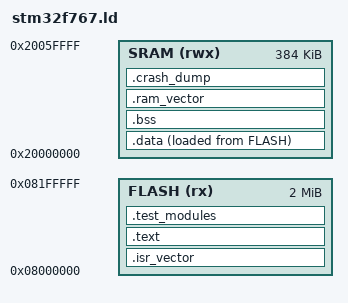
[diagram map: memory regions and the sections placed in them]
/**
 * @file stm32f767.ld
 * @brief STM32F767ZIT6 链接脚本
 */

/*============================================================================
 * 内存布局
 *============================================================================*/

MEMORY
{
    /* Flash: 2MB */
    FLASH (rx)  : ORIGIN = 0x08000000, LENGTH = 2M

    /* SRAM: 384KB */
    SRAM (rwx)  : ORIGIN = 0x20000000, LENGTH = 384K
}

/*============================================================================
 * 入口点
 *============================================================================*/

ENTRY(_reset_handler)

/*============================================================================
 * 段定义
 *============================================================================*/

SECTIONS
{
    /*--------------------------------------------
     * 向量表 - 必须在 Flash 起始位置
     *--------------------------------------------*/
    .isr_vector :
    {
        . = ALIGN(4);
        KEEP(*(.isr_vector))
        . = ALIGN(4);
    } > FLASH

    /*--------------------------------------------
     * 代码段
     *--------------------------------------------*/
    .text :
    {
        . = ALIGN(4);
        *(.text)
        *(.text*)
        *(.rodata)
        *(.rodata*)
        . = ALIGN(4);
        _etext = .;
    } > FLASH

    /*--------------------------------------------
     * 测试模块段
     *--------------------------------------------*/
    .test_modules :
    {
        . = ALIGN(4);
        __test_modules_start = .;
        KEEP(*(.test_modules))
        __test_modules_end = .;
        . = ALIGN(4);
    } > FLASH

    /*--------------------------------------------
     * 数据段
     *--------------------------------------------*/
    _sidata = LOADADDR(.data);

    .data :
    {
        . = ALIGN(4);
        _sdata = .;
        *(.data)
        *(.data*)
        . = ALIGN(4);
        _edata = .;
    } > SRAM AT > FLASH

    /*--------------------------------------------
     * BSS 段
     *--------------------------------------------*/
    .bss :
    {
        . = ALIGN(4);
        _sbss = .;
        *(.bss)
        *(.bss*)
        *(COMMON)
        . = ALIGN(4);
        _ebss = .;
    } > SRAM

    /*--------------------------------------------
     * RAM 向量表 (运行时动态注册 ISR)
     *--------------------------------------------*/
    .ram_vector (NOLOAD) : ALIGN(512)
    {
        . = ALIGN(512);
        __ram_vector_start = .;
        . = . + 0x200;          /* 128 entries x 4 bytes */
        __ram_vector_end = .;
    } > SRAM

    /*--------------------------------------------
     * Crash Dump (故障诊断，重启后保留)
     *--------------------------------------------*/
    .crash_dump (NOLOAD) : ALIGN(4)
    {
        __crash_dump_start = .;
        . = . + 128;
        __crash_dump_end = .;
    } > SRAM

    /*--------------------------------------------
     * 栈 (在 SRAM 末尾)
     *--------------------------------------------*/
    _estack = ORIGIN(SRAM) + LENGTH(SRAM);
}

/*============================================================================
 * 结束
 *============================================================================*/

END = .;
